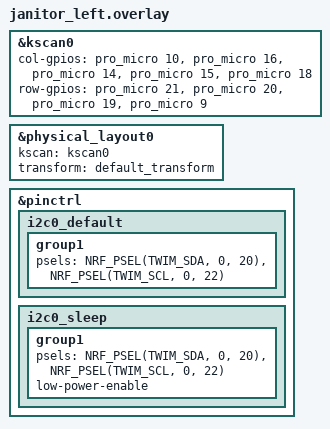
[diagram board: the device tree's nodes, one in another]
#include "janitor.dtsi"

&kscan0 {
	col-gpios
		= <&pro_micro 10 GPIO_ACTIVE_HIGH>
		, <&pro_micro 16 GPIO_ACTIVE_HIGH>
		, <&pro_micro 14 GPIO_ACTIVE_HIGH>
		, <&pro_micro 15 GPIO_ACTIVE_HIGH>
		, <&pro_micro 18 GPIO_ACTIVE_HIGH>
		;
	row-gpios
		= <&pro_micro 21 (GPIO_ACTIVE_HIGH | GPIO_PULL_DOWN)>
		, <&pro_micro 20 (GPIO_ACTIVE_HIGH | GPIO_PULL_DOWN)>
		, <&pro_micro 19 (GPIO_ACTIVE_HIGH | GPIO_PULL_DOWN)>
		, <&pro_micro 9 (GPIO_ACTIVE_HIGH | GPIO_PULL_DOWN)>
		;
};

&physical_layout0 {
	kscan = <&kscan0>;
	transform = <&default_transform>;
};

&pinctrl {
	i2c0_default: i2c0_default {
		group1 {
			psels = <NRF_PSEL(TWIM_SDA, 0, 20)>,
				<NRF_PSEL(TWIM_SCL, 0, 22)>;
		};
	};
	i2c0_sleep: i2c0_sleep {
		group1 {
			psels = <NRF_PSEL(TWIM_SDA, 0, 20)>,
				<NRF_PSEL(TWIM_SCL, 0, 22)>;
			low-power-enable;
		};
	};
};
